# adcss_ADCSS_ECC_AGGR_00729000h register map
Vendor: Texas Instruments
Peripheral module from a debugger description file (folder AM275x).
Registers are 32-bit, access not given, reset 0x0 unless marked. A register's access mark holds for its fields unless they carry their own. Offsets are as the file gives them; lines under a group give offsets from that group; [hi:lo] are bit positions; {n}, {i} and the like mark numbered series; 'fields as' and 'values as' point back to an identical list; <NAME> marks a mode.

## adcss_ecc_aggr
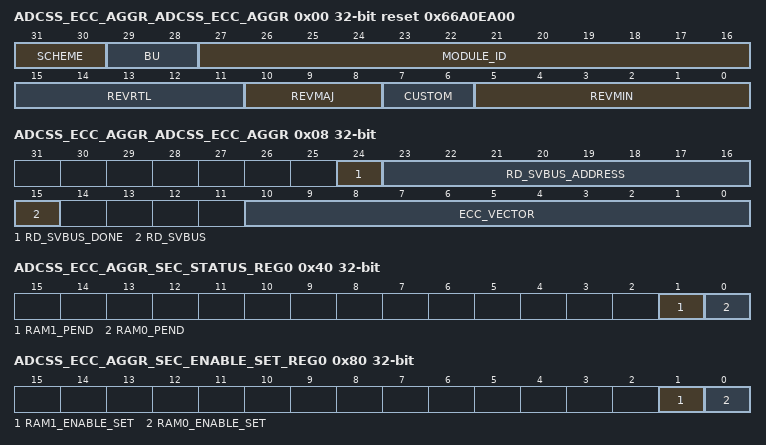
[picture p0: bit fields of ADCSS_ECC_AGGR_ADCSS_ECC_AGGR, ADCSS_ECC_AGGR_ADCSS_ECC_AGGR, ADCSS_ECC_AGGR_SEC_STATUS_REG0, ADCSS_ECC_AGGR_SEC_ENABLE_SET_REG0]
0x00 ADCSS_ECC_AGGR_ADCSS_ECC_AGGR ro reset 0x66A0EA00 — Revision parameters
  [31:30] SCHEME
  [29:28] BU — Business Unit
  [27:16] MODULE_ID
  [15:11] REVRTL — RTL version
  [10:8] REVMAJ — Major version
  [7:6] CUSTOM — Custom version
  [5:0] REVMIN — Minor version
0x08 ADCSS_ECC_AGGR_ADCSS_ECC_AGGR — ECC Vector Register
  [24] RD_SVBUS_DONE — Status to indicate if read on serial VBUS is complete, write of any value will clear this bit. (access R/W1TC)
  [23:16] RD_SVBUS_ADDRESS rw — Read address
  [15] RD_SVBUS — Write 1 to trigger a read on the serial VBUS (access R/W1TS)
  [10:0] ECC_VECTOR rw — Value written to select the corresponding ECC RAM for control or status
0x0C ADCSS_ECC_AGGR_ADCSS_ECC_AGGR ro reset 0x2 — Misc Status
  [10:0] NUM_RAMS — Indicates the number of RAMS serviced by the ECC aggregator
0x3C ADCSS_ECC_AGGR_SEC_EOI_REG — EOI Register
  [0] EOI_WR — EOI Register (access R/W1TS)
0x40 ADCSS_ECC_AGGR_SEC_STATUS_REG0 — Interrupt Status Register 0
  [1] RAM1_PEND — Interrupt Pending Status for ram1_pend (access R/W1TS)
  [0] RAM0_PEND — Interrupt Pending Status for ram0_pend (access R/W1TS)
0x80 ADCSS_ECC_AGGR_SEC_ENABLE_SET_REG0 — Interrupt Enable Set Register 0
  [1] RAM1_ENABLE_SET — Interrupt Enable Set Register for ram1_pend (access R/W1TS)
  [0] RAM0_ENABLE_SET — Interrupt Enable Set Register for ram0_pend (access R/W1TS)
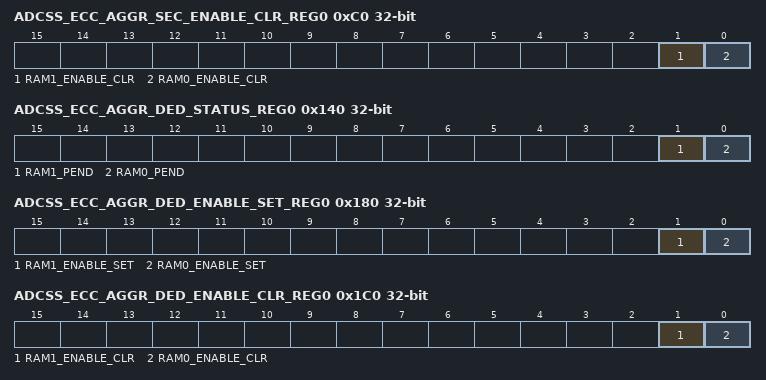
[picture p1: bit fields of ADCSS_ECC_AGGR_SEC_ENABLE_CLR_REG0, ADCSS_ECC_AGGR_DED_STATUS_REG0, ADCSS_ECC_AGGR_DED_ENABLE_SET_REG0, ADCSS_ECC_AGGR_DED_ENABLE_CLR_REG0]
0xC0 ADCSS_ECC_AGGR_SEC_ENABLE_CLR_REG0 — Interrupt Enable Clear Register 0
  [1] RAM1_ENABLE_CLR — Interrupt Enable Clear Register for ram1_pend (access R/W1TC)
  [0] RAM0_ENABLE_CLR — Interrupt Enable Clear Register for ram0_pend (access R/W1TC)
0x13C ADCSS_ECC_AGGR_DED_EOI_REG — EOI Register
  [0] EOI_WR — EOI Register (access R/W1TS)
0x140 ADCSS_ECC_AGGR_DED_STATUS_REG0 — Interrupt Status Register 0
  fields as ADCSS_ECC_AGGR_SEC_STATUS_REG0
0x180 ADCSS_ECC_AGGR_DED_ENABLE_SET_REG0 — Interrupt Enable Set Register 0
  fields as ADCSS_ECC_AGGR_SEC_ENABLE_SET_REG0
0x1C0 ADCSS_ECC_AGGR_DED_ENABLE_CLR_REG0 — Interrupt Enable Clear Register 0
  fields as ADCSS_ECC_AGGR_SEC_ENABLE_CLR_REG0
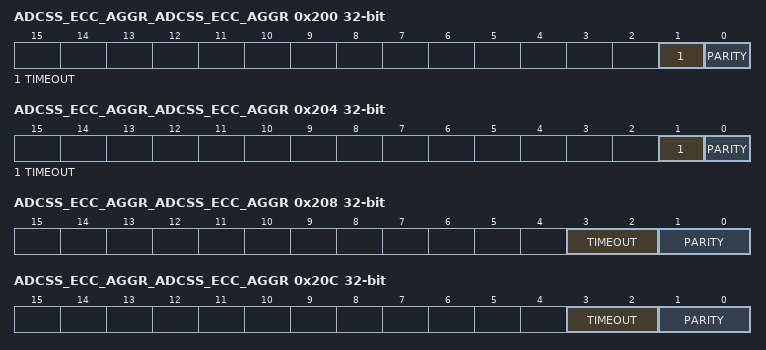
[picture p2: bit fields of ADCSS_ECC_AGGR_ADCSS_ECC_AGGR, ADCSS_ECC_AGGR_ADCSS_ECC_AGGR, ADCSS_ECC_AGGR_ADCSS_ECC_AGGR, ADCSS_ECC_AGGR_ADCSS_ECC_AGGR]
0x200 ADCSS_ECC_AGGR_ADCSS_ECC_AGGR — AGGR interrupt enable set Register
  [1] TIMEOUT — interrupt enable set for svbus timeout errors (access R/W1TS)
  [0] PARITY — interrupt enable set for parity errors (access R/W1TS)
0x204 ADCSS_ECC_AGGR_ADCSS_ECC_AGGR — AGGR interrupt enable clear Register
  [1] TIMEOUT — interrupt enable clear for svbus timeout errors (access R/W1TC)
  [0] PARITY — interrupt enable clear for parity errors (access R/W1TC)
0x208 ADCSS_ECC_AGGR_ADCSS_ECC_AGGR — AGGR interrupt status set Register
  [3:2] TIMEOUT — interrupt status set for svbus timeout errors (access R/WI)
  [1:0] PARITY — interrupt status set for parity errors (access R/WI)
0x20C ADCSS_ECC_AGGR_ADCSS_ECC_AGGR — AGGR interrupt status clear Register
  [3:2] TIMEOUT — interrupt status clear for svbus timeout errors (access R/WD)
  [1:0] PARITY — interrupt status clear for parity errors (access R/WD)
